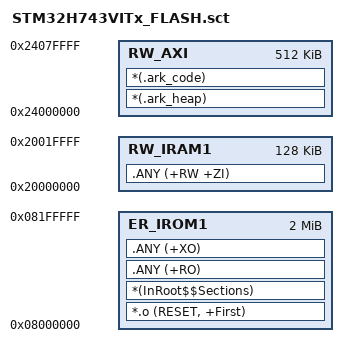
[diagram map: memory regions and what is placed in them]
; Ark C Compiler - MDK STM32H743 - scatter 文件
; STM32H743VI: 2 MB Flash @ 0x08000000, 1 MB SRAM 总量
;   DTCM 128KB @ 0x20000000
;   AXI  512KB @ 0x24000000
;   SRAM1+2+3+4 共约 384KB (本工程未使用)
;
; ER_IROM1 : Flash 代码
; RW_IRAM1 : DTCM 给 .data/.bss/stack/heap
; RW_AXI   : AXI SRAM 给 ArkCC 的堆与代码缓冲 (.ark_heap / .ark_code)

LR_IROM1 0x08000000 0x00200000  {
  ER_IROM1 0x08000000 0x00200000  {
    *.o (RESET, +First)
    *(InRoot$$Sections)
    .ANY (+RO)
    .ANY (+XO)
  }

  ; DTCM —— RW/ZI、栈、堆
  RW_IRAM1 0x20000000 0x00020000  {
    .ANY (+RW +ZI)
  }

  ; AXI SRAM —— ArkCC 专用段
  RW_AXI 0x24000000 0x00080000  {
    *(.ark_heap)
    *(.ark_code)
  }
}
